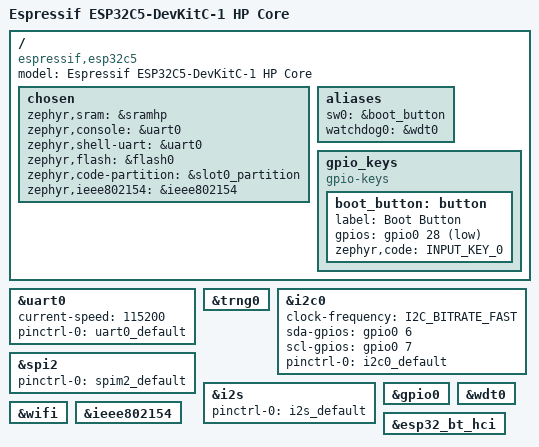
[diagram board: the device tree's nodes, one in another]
/*
 * Copyright (c) 2026 Espressif Systems (Shanghai) Co., Ltd.
 *
 * SPDX-License-Identifier: Apache-2.0
 */

/dts-v1/;

#include <espressif/esp32c5/esp32c5_wroom_n8r4.dtsi>
#include "esp32c5_devkitc_hpcore-pinctrl.dtsi"
#include <zephyr/dt-bindings/input/input-event-codes.h>
#include <espressif/partitions_0x2000_default_8M.dtsi>

/ {
	model = "Espressif ESP32C5-DevKitC-1 HP Core";
	compatible = "espressif,esp32c5";

	chosen {
		zephyr,sram = &sramhp;
		zephyr,console = &uart0;
		zephyr,shell-uart = &uart0;
		zephyr,flash = &flash0;
		zephyr,code-partition = &slot0_partition;
		zephyr,ieee802154 = &ieee802154;
	};

	aliases {
		sw0 = &boot_button;
		watchdog0 = &wdt0;
	};

	gpio_keys {
		compatible = "gpio-keys";

		boot_button: button {
			label = "Boot Button";
			gpios = <&gpio0 28 (GPIO_PULL_UP | GPIO_ACTIVE_LOW)>;
			zephyr,code = <INPUT_KEY_0>;
		};
	};
};

&uart0 {
	status = "okay";
	current-speed = <115200>;
	pinctrl-0 = <&uart0_default>;
	pinctrl-names = "default";
};

&trng0 {
	status = "okay";
};

&i2c0 {
	status = "okay";
	clock-frequency = <I2C_BITRATE_FAST>;
	sda-gpios = <&gpio0 6 GPIO_OPEN_DRAIN>;
	scl-gpios = <&gpio0 7 GPIO_OPEN_DRAIN>;
	pinctrl-0 = <&i2c0_default>;
	pinctrl-names = "default";
};

&spi2 {
	#address-cells = <1>;
	#size-cells = <0>;
	status = "okay";
	pinctrl-0 = <&spim2_default>;
	pinctrl-names = "default";
};

&i2s {
	pinctrl-0 = <&i2s_default>;
	pinctrl-names = "default";
};

&gpio0 {
	status = "okay";
};

&wdt0 {
	status = "okay";
};

&wifi {
	status = "okay";
};

&ieee802154 {
	status = "okay";
};

&esp32_bt_hci {
	status = "okay";
};
